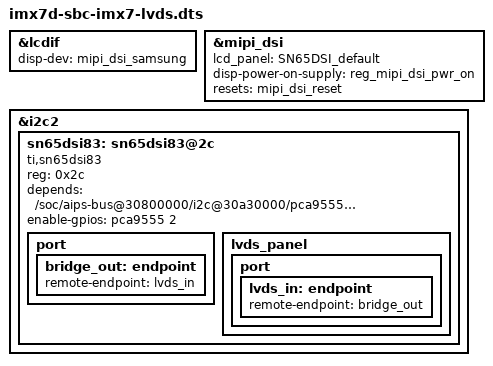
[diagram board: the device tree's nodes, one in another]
/*
 * Copyright (C) 2017 CompuLab Ltd.
 *
 * This program is free software; you can redistribute it and/or modify
 * it under the terms of the GNU General Public License version 2 as
 * published by the Free Software Foundation.
 */

#include "imx7d-sbc-imx7.dts"

&lcdif {
	disp-dev = "mipi_dsi_samsung";
};

&mipi_dsi {
	lcd_panel = "SN65DSI_default";
	disp-power-on-supply = <&reg_mipi_dsi_pwr_on>;
	resets = <&mipi_dsi_reset>;
	status = "okay";
};

&i2c2 {
	sn65dsi83: sn65dsi83@2c {
		compatible = "ti,sn65dsi83";
		reg=<0x2c>;
		depends = "/soc/aips-bus@30800000/i2c@30a30000/pca9555@20";
		enable-gpios = <&pca9555 2 GPIO_ACTIVE_HIGH>;
		status = "okay";

		port {
			bridge_out: endpoint{
				remote-endpoint = <&lvds_in>;
			};
		};

		lvds_panel {
			port {
				lvds_in: endpoint{
					remote-endpoint = <&bridge_out>;
				};
			};
		};
	};
};
